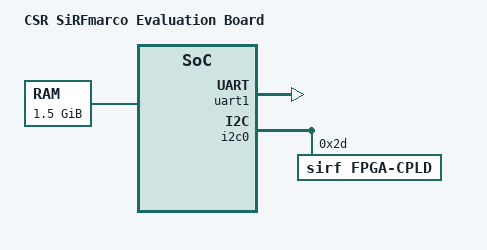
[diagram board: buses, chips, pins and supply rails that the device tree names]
/*
 * DTS file for CSR SiRFmarco Evaluation Board
 *
 * Copyright (c) 2012 Cambridge Silicon Radio Limited, a CSR plc group company.
 *
 * Licensed under GPLv2 or later.
 */

/dts-v1/;

/include/ "marco.dtsi"

/ {
	model = "CSR SiRFmarco Evaluation Board";
	compatible = "sirf,marco", "sirf,marco-cb";

	memory {
		reg = <0x40000000 0x60000000>;
	};

	axi {
		peri-iobg {
			uart1: uart@cc060000 {
				status = "okay";
			};
			i2c0: i2c@cc0e0000 {
			      status = "okay";
			      fpga-cpld@2d {
				      compatible = "sirf,fpga-cpld";
				      reg = <0x2d>;
			      };
			};
			pci-iobg {
				sd0: sdhci@cd000000 {
					bus-width = <8>;
				};
			};
		};
	};
};
